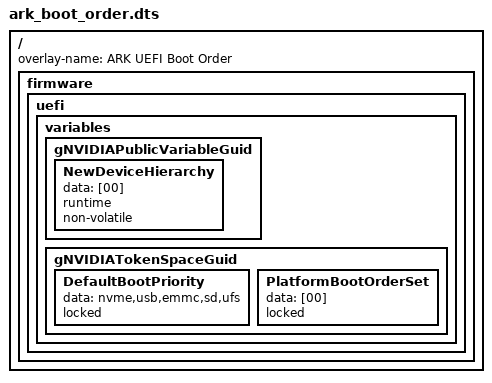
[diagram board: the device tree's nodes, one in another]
// SPDX-License-Identifier: GPL-2.0-only
// SPDX-FileCopyrightText: Copyright (c) 2026, ARK Electronics.

/dts-v1/;
/plugin/;

/*
 * UEFI boot order, layered over the BSP's L4TConfiguration.dtbo.
 *
 * UEFI sorts BootOrder by DefaultBootPriority once, sets PlatformBootOrderSet, and
 * never sorts again. Every option it re-discovers afterwards (the SSD after one boot
 * without it, a NIC's four PXE/HTTP options) lands at the top or bottom per
 * NewDeviceHierarchy, so the SSD can end up behind four DHCP timeouts and the UEFI
 * Shell, which never returns. Locking PlatformBootOrderSet false makes UEFI re-sort
 * on every boot. A reorder made in the UEFI menu is undone on the next boot; F11's
 * one-time boot still works.
 *
 * DefaultBootPriority is stock apart from moving nvme ahead of usb: every product
 * flashes to NVMe, and an inserted USB stick must not outrank the installed
 * system. A --usb build still boots — with no NVMe present, usb is simply next.
 */

/ {
	overlay-name = "ARK UEFI Boot Order";

	fragment@0 {
		target-path = "/";

		board_config {
			sw-modules = "uefi";
		};

		__overlay__ {

			firmware {

				uefi {

					variables {

						gNVIDIAPublicVariableGuid {

							NewDeviceHierarchy {
								data = [00];
								runtime;
								non-volatile;
							};
						};

						gNVIDIATokenSpaceGuid {

							DefaultBootPriority {
								data = "nvme,usb,emmc,sd,ufs";
								locked;
							};

							PlatformBootOrderSet {
								data = [00];
								locked;
							};
						};
					};
				};
			};
		};
	};
};
